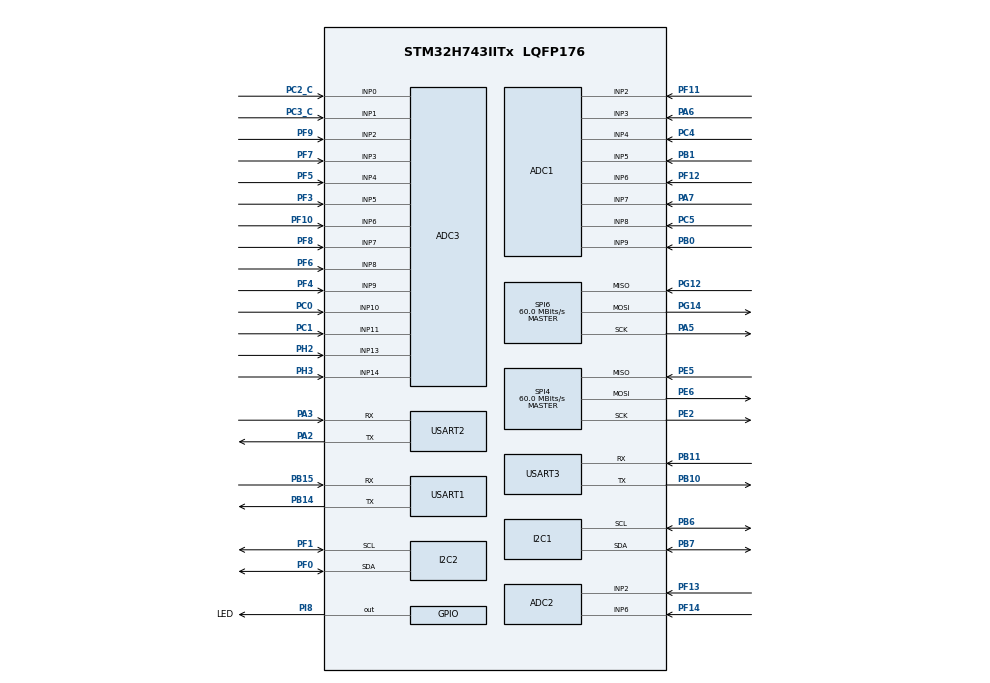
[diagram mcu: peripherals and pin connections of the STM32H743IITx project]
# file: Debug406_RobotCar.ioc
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ADC1.Channel-0\#ChannelRegularConversion=ADC_CHANNEL_2
ADC1.ClockPrescaler=ADC_CLOCK_ASYNC_DIV4
ADC1.NbrOfConversionFlag=1
ADC1.OffsetNumber-0\#ChannelRegularConversion=ADC_OFFSET_NONE
ADC1.OffsetSignedSaturation-0\#ChannelRegularConversion=DISABLE
ADC1.Rank-0\#ChannelRegularConversion=1
ADC1.SamplingTime-0\#ChannelRegularConversion=ADC_SAMPLETIME_16CYCLES_5
ADC1.master=1
ADC2.Channel-0\#ChannelRegularConversion=ADC_CHANNEL_3
ADC2.ClockPrescaler=ADC_CLOCK_ASYNC_DIV4
ADC2.NbrOfConversionFlag=1
ADC2.OffsetNumber-0\#ChannelRegularConversion=ADC_OFFSET_NONE
ADC2.OffsetSignedSaturation-0\#ChannelRegularConversion=DISABLE
ADC2.Rank-0\#ChannelRegularConversion=1
ADC2.SamplingTime-0\#ChannelRegularConversion=ADC_SAMPLETIME_16CYCLES_5
ADC3.Channel-0\#ChannelRegularConversion=ADC_CHANNEL_0
ADC3.ClockPrescaler=ADC_CLOCK_ASYNC_DIV4
ADC3.NbrOfConversionFlag=1
ADC3.OffsetNumber-0\#ChannelRegularConversion=ADC_OFFSET_NONE
ADC3.OffsetSignedSaturation-0\#ChannelRegularConversion=DISABLE
ADC3.Rank-0\#ChannelRegularConversion=1
ADC3.SamplingTime-0\#ChannelRegularConversion=ADC_SAMPLETIME_16CYCLES_5
I2C1.Timing=0x307075B1
I2C2.Timing=0x307075B1
Mcu.Family=STM32H7
Mcu.Name=STM32H743IITx
Mcu.Package=LQFP176
NVIC.PriorityGroup=NVIC_PRIORITYGROUP_4
PA13\ (JTMS/SWDIO).Mode=Serial_Wire
PA13\ (JTMS/SWDIO).Signal=DEBUG_JTMS-SWDIO
PA14\ (JTCK/SWCLK).Mode=Serial_Wire
PA14\ (JTCK/SWCLK).Signal=DEBUG_JTCK-SWCLK
PA2.Mode=Asynchronous
PA2.Signal=USART2_TX
PA3.Mode=Asynchronous
PA3.Signal=USART2_RX
PA5.Mode=Full_Duplex_Master
PA5.Signal=SPI6_SCK
PA6.Signal=ADCx_INP3
PA7.Signal=ADCx_INP7
PB0.Signal=ADCx_INP9
PB1.Signal=ADCx_INP5
PB10.Mode=Asynchronous
PB10.Signal=USART3_TX
PB11.Mode=Asynchronous
PB11.Signal=USART3_RX
PB14.GPIO_Speed=GPIO_SPEED_FREQ_VERY_HIGH
PB14.Mode=Asynchronous
PB14.Signal=USART1_TX
PB15.GPIO_Speed=GPIO_SPEED_FREQ_VERY_HIGH
PB15.Mode=Asynchronous
PB15.Signal=USART1_RX
PB6.Mode=I2C
PB6.Signal=I2C1_SCL
PB7.Mode=I2C
PB7.Signal=I2C1_SDA
PC0.Signal=ADCx_INP10
PC1.Signal=ADCx_INP11
PC2_C.Mode=IN0-Single-Ended
PC2_C.Signal=ADC3_INP0
PC3_C.Mode=IN1-Single-Ended
PC3_C.Signal=ADC3_INP1
PC4.Signal=ADCx_INP4
PC5.Signal=ADCx_INP8
PE2.Mode=Full_Duplex_Master
PE2.Signal=SPI4_SCK
PE5.Mode=Full_Duplex_Master
PE5.Signal=SPI4_MISO
PE6.Mode=Full_Duplex_Master
PE6.Signal=SPI4_MOSI
PF0.Mode=I2C
PF0.Signal=I2C2_SDA
PF1.Mode=I2C
PF1.Signal=I2C2_SCL
PF10.Mode=IN6-Single-Ended
PF10.Signal=ADC3_INP6
PF11.Mode=IN2-Single-Ended
PF11.Signal=ADC1_INP2
PF12.Mode=IN6-Single-Ended
PF12.Signal=ADC1_INP6
PF13.Mode=IN2-Single-Ended
PF13.Signal=ADC2_INP2
PF14.Mode=IN6-Single-Ended
PF14.Signal=ADC2_INP6
PF3.Mode=IN5-Single-Ended
PF3.Signal=ADC3_INP5
PF4.Mode=IN9-Single-Ended
PF4.Signal=ADC3_INP9
PF5.Mode=IN4-Single-Ended
PF5.Signal=ADC3_INP4
PF6.Mode=IN8-Single-Ended
PF6.Signal=ADC3_INP8
PF7.Mode=IN3-Single-Ended
PF7.Signal=ADC3_INP3
PF8.Mode=IN7-Single-Ended
PF8.Signal=ADC3_INP7
PF9.Mode=IN2-Single-Ended
PF9.Signal=ADC3_INP2
PG12.Mode=Full_Duplex_Master
PG12.Signal=SPI6_MISO
PG14.Mode=Full_Duplex_Master
PG14.Signal=SPI6_MOSI
PH0-OSC_IN\ (PH0).Mode=HSE-External-Oscillator
PH0-OSC_IN\ (PH0).Signal=RCC_OSC_IN
PH1-OSC_OUT\ (PH1).Mode=HSE-External-Oscillator
PH1-OSC_OUT\ (PH1).Signal=RCC_OSC_OUT
PH2.Mode=IN13-Single-Ended
PH2.Signal=ADC3_INP13
PH3.Mode=IN14-Single-Ended
PH3.Signal=ADC3_INP14
PI8.GPIO_Label=LED
PI8.Signal=GPIO_Output
ProjectManager.HeapSize=0x200
ProjectManager.StackSize=0x400
ProjectManager.TargetToolchain=MDK-ARM V5.27
RCC.ADCFreq_Value=30000000
RCC.APB1Freq_Value=120000000
RCC.APB2Freq_Value=120000000
RCC.APB3Freq_Value=120000000
RCC.APB4Freq_Value=120000000
RCC.CortexFreq_Value=480000000
RCC.D1PPRE=RCC_APB3_DIV2
RCC.D2PPRE1=RCC_APB1_DIV2
RCC.D2PPRE2=RCC_APB2_DIV2
RCC.D3PPRE=RCC_APB4_DIV2
RCC.DIVM1=5
RCC.DIVM2=2
RCC.DIVN1=192
RCC.DIVN2=12
RCC.DIVP2=5
RCC.EnbaleCSS=true
RCC.HCLKFreq_Value=240000000
RCC.HPRE=RCC_HCLK_DIV2
RCC.PLL2FRACN=0
RCC.PLL3FRACN=0
RCC.PLLFRACN=0
RCC.PLLSourceVirtual=RCC_PLLSOURCE_HSE
RCC.SYSCLKFreq_VALUE=480000000
RCC.SYSCLKSource=RCC_SYSCLKSOURCE_PLLCLK
RCC.USBFreq_Value=480000000
SH.ADCx_INP10.0=ADC3_INP10,IN10-Single-Ended
SH.ADCx_INP11.0=ADC3_INP11,IN11-Single-Ended
SH.ADCx_INP3.0=ADC1_INP3,IN3-Single-Ended
SH.ADCx_INP3.1=ADC2_INP3,IN3-Single-Ended
SH.ADCx_INP4.0=ADC1_INP4,IN4-Single-Ended
SH.ADCx_INP4.1=ADC2_INP4,IN4-Single-Ended
SH.ADCx_INP5.0=ADC1_INP5,IN5-Single-Ended
SH.ADCx_INP5.1=ADC2_INP5,IN5-Single-Ended
SH.ADCx_INP7.0=ADC1_INP7,IN7-Single-Ended
SH.ADCx_INP7.1=ADC2_INP7,IN7-Single-Ended
SH.ADCx_INP8.0=ADC1_INP8,IN8-Single-Ended
SH.ADCx_INP8.1=ADC2_INP8,IN8-Single-Ended
SH.ADCx_INP9.0=ADC1_INP9,IN9-Single-Ended
SH.ADCx_INP9.1=ADC2_INP9,IN9-Single-Ended
SPI4.CalculateBaudRate=60.0 MBits/s
SPI4.Direction=SPI_DIRECTION_2LINES
SPI4.Mode=SPI_MODE_MASTER
SPI4.VirtualType=VM_MASTER
SPI6.CalculateBaudRate=60.0 MBits/s
SPI6.Direction=SPI_DIRECTION_2LINES
SPI6.Mode=SPI_MODE_MASTER
SPI6.VirtualType=VM_MASTER
USART1.VirtualMode-Asynchronous=VM_ASYNC
USART2.VirtualMode-Asynchronous=VM_ASYNC
USART3.VirtualMode-Asynchronous=VM_ASYNC
VP_TIM1_VS_ClockSourceINT.Mode=Internal
VP_TIM2_VS_ClockSourceINT.Mode=Internal
VP_TIM3_VS_ClockSourceINT.Mode=Internal
board=custom

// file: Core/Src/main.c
/* USER CODE BEGIN Header */
/**
  ******************************************************************************
  * @file           : main.c
  * @brief          : Main program body
  ******************************************************************************
  * @attention
  *
  * <h2><center>&copy; Copyright (c) 2020 STMicroelectronics.
  * All rights reserved.</center></h2>
  *
  * This software component is licensed by ST under BSD 3-Clause license,
  * the "License"; You may not use this file except in compliance with the
  * License. You may obtain a copy of the License at:
  *                        opensource.org/licenses/BSD-3-Clause
  *
  ******************************************************************************
  */
/* USER CODE END Header */
#include "main.h"
#include "adc.h"
#include "i2c.h"
#include "spi.h"
#include "tim.h"
#include "usart.h"
#include "gpio.h"

/* USER CODE BEGIN Includes */
#include "UserMain.h"
/* USER CODE END Includes */

void SystemClock_Config(void);

int main(void)
{

  /* MCU Configuration--------------------------------------------------------*/

  /* Reset of all peripherals, Initializes the Flash interface and the Systick. */
  HAL_Init();

  /* Configure the system clock */
  SystemClock_Config();

  /* Initialize all configured peripherals */
  MX_GPIO_Init();
  MX_USART1_UART_Init();
  MX_ADC1_Init();
  MX_ADC2_Init();
  MX_ADC3_Init();
  MX_I2C1_Init();
  MX_I2C2_Init();
  MX_SPI4_Init();
  MX_SPI6_Init();
  MX_TIM1_Init();
  MX_TIM2_Init();
  MX_TIM3_Init();
  MX_USART2_UART_Init();
  MX_USART3_UART_Init();
  /* USER CODE BEGIN 2 */
	UserInit();
  /* USER CODE END 2 */

  /* Infinite loop */
  /* USER CODE BEGIN WHILE */
  while (1)
  {
		UserLoop();
    /* USER CODE END WHILE */

  }
}

void SystemClock_Config(void)
{
  RCC_OscInitTypeDef RCC_OscInitStruct = {0};
  RCC_ClkInitTypeDef RCC_ClkInitStruct = {0};
  RCC_PeriphCLKInitTypeDef PeriphClkInitStruct = {0};

  /** Supply configuration update enable
  */
  HAL_PWREx_ConfigSupply(PWR_LDO_SUPPLY);
  /** Configure the main internal regulator output voltage
  */
  __HAL_PWR_VOLTAGESCALING_CONFIG(PWR_REGULATOR_VOLTAGE_SCALE0);

  while(!__HAL_PWR_GET_FLAG(PWR_FLAG_VOSRDY)) {}
  /** Macro to configure the PLL clock source
  */
  __HAL_RCC_PLL_PLLSOURCE_CONFIG(RCC_PLLSOURCE_HSE);
  /** Initializes the RCC Oscillators according to the specified parameters
  * in the RCC_OscInitTypeDef structure.
  */
  RCC_OscInitStruct.OscillatorType = RCC_OSCILLATORTYPE_HSE;
  RCC_OscInitStruct.HSEState = RCC_HSE_ON;
  RCC_OscInitStruct.PLL.PLLState = RCC_PLL_ON;
  RCC_OscInitStruct.PLL.PLLSource = RCC_PLLSOURCE_HSE;
  RCC_OscInitStruct.PLL.PLLM = 5;
  RCC_OscInitStruct.PLL.PLLN = 192;
  RCC_OscInitStruct.PLL.PLLP = 2;
  RCC_OscInitStruct.PLL.PLLQ = 2;
  RCC_OscInitStruct.PLL.PLLR = 2;
  RCC_OscInitStruct.PLL.PLLRGE = RCC_PLL1VCIRANGE_2;
  RCC_OscInitStruct.PLL.PLLVCOSEL = RCC_PLL1VCOWIDE;
  RCC_OscInitStruct.PLL.PLLFRACN = 0;
  if (HAL_RCC_OscConfig(&RCC_OscInitStruct) != HAL_OK)
  {
    Error_Handler();
  }
  /** Initializes the CPU, AHB and APB buses clocks
  */
  RCC_ClkInitStruct.ClockType = RCC_CLOCKTYPE_HCLK|RCC_CLOCKTYPE_SYSCLK
                              |RCC_CLOCKTYPE_PCLK1|RCC_CLOCKTYPE_PCLK2
                              |RCC_CLOCKTYPE_D3PCLK1|RCC_CLOCKTYPE_D1PCLK1;
  RCC_ClkInitStruct.SYSCLKSource = RCC_SYSCLKSOURCE_PLLCLK;
  RCC_ClkInitStruct.SYSCLKDivider = RCC_SYSCLK_DIV1;
  RCC_ClkInitStruct.AHBCLKDivider = RCC_HCLK_DIV2;
  RCC_ClkInitStruct.APB3CLKDivider = RCC_APB3_DIV2;
  RCC_ClkInitStruct.APB1CLKDivider = RCC_APB1_DIV2;
  RCC_ClkInitStruct.APB2CLKDivider = RCC_APB2_DIV2;
  RCC_ClkInitStruct.APB4CLKDivider = RCC_APB4_DIV2;

  if (HAL_RCC_ClockConfig(&RCC_ClkInitStruct, FLASH_LATENCY_4) != HAL_OK)
  {
    Error_Handler();
  }
  PeriphClkInitStruct.PeriphClockSelection = RCC_PERIPHCLK_USART3|RCC_PERIPHCLK_USART2
                              |RCC_PERIPHCLK_USART1|RCC_PERIPHCLK_SPI4
                              |RCC_PERIPHCLK_I2C2|RCC_PERIPHCLK_ADC
                              |RCC_PERIPHCLK_I2C1|RCC_PERIPHCLK_SPI6;
  PeriphClkInitStruct.PLL2.PLL2M = 2;
  PeriphClkInitStruct.PLL2.PLL2N = 12;
  PeriphClkInitStruct.PLL2.PLL2P = 5;
  PeriphClkInitStruct.PLL2.PLL2Q = 2;
  PeriphClkInitStruct.PLL2.PLL2R = 2;
  PeriphClkInitStruct.PLL2.PLL2RGE = RCC_PLL2VCIRANGE_3;
  PeriphClkInitStruct.PLL2.PLL2VCOSEL = RCC_PLL2VCOMEDIUM;
  PeriphClkInitStruct.PLL2.PLL2FRACN = 0;
  PeriphClkInitStruct.Spi45ClockSelection = RCC_SPI45CLKSOURCE_D2PCLK1;
  PeriphClkInitStruct.Usart234578ClockSelection = RCC_USART234578CLKSOURCE_D2PCLK1;
  PeriphClkInitStruct.Usart16ClockSelection = RCC_USART16CLKSOURCE_D2PCLK2;
  PeriphClkInitStruct.I2c123ClockSelection = RCC_I2C123CLKSOURCE_D2PCLK1;
  PeriphClkInitStruct.AdcClockSelection = RCC_ADCCLKSOURCE_PLL2;
  PeriphClkInitStruct.Spi6ClockSelection = RCC_SPI6CLKSOURCE_D3PCLK1;
  if (HAL_RCCEx_PeriphCLKConfig(&PeriphClkInitStruct) != HAL_OK)
  {
    Error_Handler();
  }
  /** Enables the Clock Security System
  */
  HAL_RCC_EnableCSS();
}

void Error_Handler(void)
{
  __disable_irq();
  while (1)
  {
  }
}

/************************ (C) COPYRIGHT STMicroelectronics *****END OF FILE****/
